AUTOSAR XML (schema 4-0-3)
package /ComponentTypes
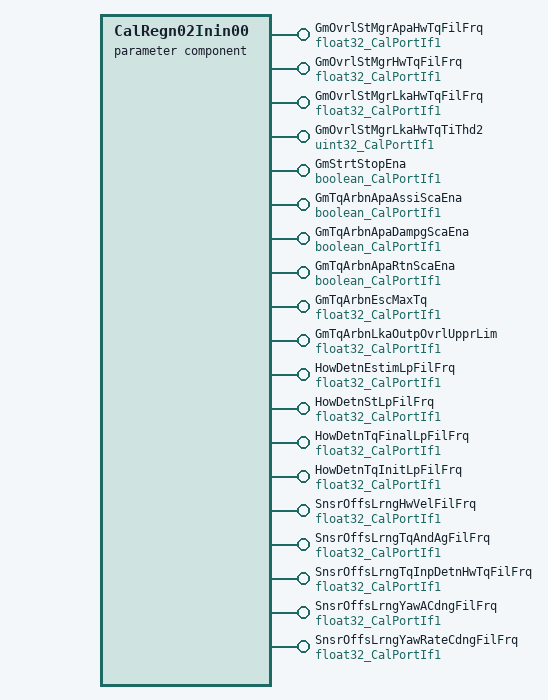
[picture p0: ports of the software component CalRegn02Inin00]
  parameter sw component type CalRegn02Inin00
    19 x provide port:
      GmOvrlStMgrApaHwTqFilFrq: parameter-provide-com-spec{init-value=10, parameter=Val}, provided-interface=float32_CalPortIf1
      GmOvrlStMgrHwTqFilFrq: parameter-provide-com-spec{init-value=10, parameter=Val}, provided-interface=float32_CalPortIf1
      GmOvrlStMgrLkaHwTqFilFrq: parameter-provide-com-spec{init-value=10, parameter=Val}, provided-interface=float32_CalPortIf1
      GmOvrlStMgrLkaHwTqTiThd2: parameter-provide-com-spec{init-value=100, parameter=Val}, provided-interface=uint32_CalPortIf1
      GmStrtStopEna: parameter-provide-com-spec{init-value=1, parameter=Logl}, provided-interface=boolean_CalPortIf1
      GmTqArbnApaAssiScaEna: parameter-provide-com-spec{init-value=1, parameter=Logl}, provided-interface=boolean_CalPortIf1
      GmTqArbnApaDampgScaEna: parameter-provide-com-spec{init-value=1, parameter=Logl}, provided-interface=boolean_CalPortIf1
      GmTqArbnApaRtnScaEna: parameter-provide-com-spec{init-value=1, parameter=Logl}, provided-interface=boolean_CalPortIf1
      GmTqArbnEscMaxTq: parameter-provide-com-spec{init-value=3, parameter=Val}, provided-interface=float32_CalPortIf1
      GmTqArbnLkaOutpOvrlUpprLim: parameter-provide-com-spec{init-value=0.15, parameter=Val}, provided-interface=float32_CalPortIf1
      HowDetnEstimLpFilFrq: parameter-provide-com-spec{init-value=0.5, parameter=Val}, provided-interface=float32_CalPortIf1
      HowDetnStLpFilFrq: parameter-provide-com-spec{init-value=2, parameter=Val}, provided-interface=float32_CalPortIf1
      HowDetnTqFinalLpFilFrq: parameter-provide-com-spec{init-value=1, parameter=Val}, provided-interface=float32_CalPortIf1
      HowDetnTqInitLpFilFrq: parameter-provide-com-spec{init-value=7, parameter=Val}, provided-interface=float32_CalPortIf1
      SnsrOffsLrngHwVelFilFrq: parameter-provide-com-spec{init-value=250, parameter=Val}, provided-interface=float32_CalPortIf1
      SnsrOffsLrngTqAndAgFilFrq: parameter-provide-com-spec{init-value=250, parameter=Val}, provided-interface=float32_CalPortIf1
      SnsrOffsLrngTqInpDetnHwTqFilFrq: parameter-provide-com-spec{init-value=4, parameter=Val}, provided-interface=float32_CalPortIf1
      SnsrOffsLrngYawACdngFilFrq: parameter-provide-com-spec{init-value=250, parameter=Val}, provided-interface=float32_CalPortIf1
      SnsrOffsLrngYawRateCdngFilFrq: parameter-provide-com-spec{init-value=250, parameter=Val}, provided-interface=float32_CalPortIf1
